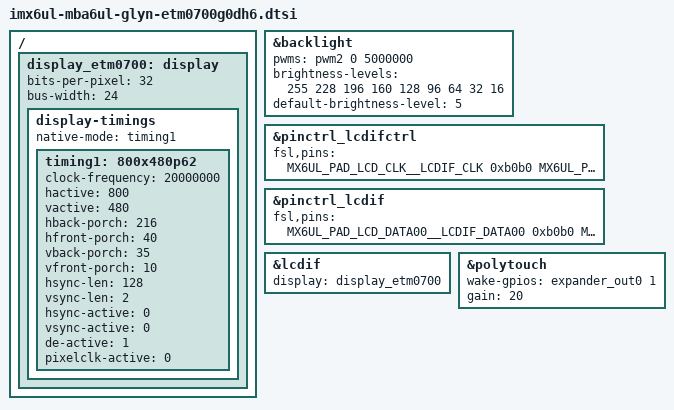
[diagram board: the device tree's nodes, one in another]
/*
 * Copyright 2016 Marco Felsch, TQ Systems GmbH
 *
 * The code contained herein is licensed under the GNU General Public
 * License. You may obtain a copy of the GNU General Public License
 * Version 2 or later at the following locations:
 *
 * http://www.opensource.org/licenses/gpl-license.html
 * http://www.gnu.org/copyleft/gpl.html
 */

/ {
	/* ETM0700G0DH6 */
	display_etm0700: display {
		bits-per-pixel = <32>; /* 32: RGB8880 mode */
		bus-width = <24>; 

		display-timings {
			native-mode = <&timing1>;
			timing1: 800x480p62 {
				/* clock-frequency = <33260000>; */
				clock-frequency = <20000000>;
				hactive = <800>;
				vactive = <480>;
				hback-porch = <216>;
				hfront-porch = <40>;
				vback-porch = <35>;
				vfront-porch = <10>;
				hsync-len = <128>;
				vsync-len = <2>;
				hsync-active = <0>;
				vsync-active = <0>;
				de-active = <1>;
				pixelclk-active = <0>;
			};
		};
	};
};

&backlight {
	pwms = <&pwm2 0 5000000>;
	brightness-levels = <255 228 196 160 128 96 64 32 16>;
	default-brightness-level = <5>;
	status = "okay";
};

&pinctrl_lcdifctrl {
	fsl,pins = <
		MX6UL_PAD_LCD_CLK__LCDIF_CLK		0xb0b0
		MX6UL_PAD_LCD_ENABLE__LCDIF_ENABLE	0xb0b0
		MX6UL_PAD_LCD_HSYNC__GPIO3_IO02		0xb0b0
		MX6UL_PAD_LCD_VSYNC__GPIO3_IO03		0xb0b0
	>;
};

&pinctrl_lcdif {
	fsl,pins = <
		MX6UL_PAD_LCD_DATA00__LCDIF_DATA00	0xb0b0
		MX6UL_PAD_LCD_DATA01__LCDIF_DATA01	0xb0b0
		MX6UL_PAD_LCD_DATA02__LCDIF_DATA02	0xb0b0
		MX6UL_PAD_LCD_DATA03__LCDIF_DATA03	0xb0b0
		MX6UL_PAD_LCD_DATA04__LCDIF_DATA04	0xb0b0
		MX6UL_PAD_LCD_DATA05__LCDIF_DATA05	0xb0b0
		MX6UL_PAD_LCD_DATA06__LCDIF_DATA06	0xb0b0
		MX6UL_PAD_LCD_DATA07__LCDIF_DATA07	0xb0b0
		MX6UL_PAD_LCD_DATA08__LCDIF_DATA08	0xb0b0
		MX6UL_PAD_LCD_DATA09__LCDIF_DATA09	0xb0b0
		MX6UL_PAD_LCD_DATA10__LCDIF_DATA10	0xb0b0
		MX6UL_PAD_LCD_DATA11__LCDIF_DATA11	0xb0b0
		MX6UL_PAD_LCD_DATA12__LCDIF_DATA12	0xb0b0
		MX6UL_PAD_LCD_DATA13__LCDIF_DATA13	0xb0b0
		MX6UL_PAD_LCD_DATA14__LCDIF_DATA14	0xb0b0
		MX6UL_PAD_LCD_DATA15__LCDIF_DATA15	0xb0b0
		MX6UL_PAD_LCD_DATA16__LCDIF_DATA16	0xb0b0
		MX6UL_PAD_LCD_DATA17__LCDIF_DATA17	0xb0b0
		MX6UL_PAD_LCD_DATA18__LCDIF_DATA18	0xb0b0
		MX6UL_PAD_LCD_DATA19__LCDIF_DATA19	0xb0b0
		MX6UL_PAD_LCD_DATA20__LCDIF_DATA20	0xb0b0
		MX6UL_PAD_LCD_DATA21__LCDIF_DATA21	0xb0b0
		MX6UL_PAD_LCD_DATA22__LCDIF_DATA22	0xb0b0
		MX6UL_PAD_LCD_DATA23__LCDIF_DATA23	0xb0b0
	>;
};

&lcdif {
	display = <&display_etm0700>;
	status = "okay";
};

&polytouch {
	wake-gpios = <&expander_out0 1 GPIO_ACTIVE_HIGH>;
	/* reset-gpios is controlled by stk reset */
	gain = <20>;

	/*
	 * HACKHACK:
	 * do not use size settings, display touch reads
	 * out 1792 x 1024 (tested with ETM0700G0DH6)
	 */

	status = "okay";
};
